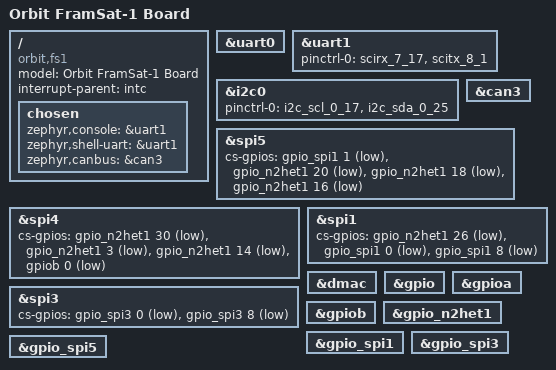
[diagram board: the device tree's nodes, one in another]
/dts-v1/;

#include <zephyr/dt-bindings/gpio/gpio.h>

#include <arm/ti/tms570ls1224.dtsi>
#include <ti/tms570/tms570ls1224-pinctrl.dtsi>

/ {
    model = "Orbit FramSat-1 Board";
    compatible = "orbit,fs1";
    interrupt-parent = <&intc>;

    chosen {
        zephyr,console = &uart1;
        zephyr,shell-uart = &uart1;
        zephyr,canbus = &can3;
    };
};

&uart0 {
    status = "okay";

};

&uart1 {
    status = "okay";
    pinctrl-0 = <&scirx_7_17 &scitx_8_1>;
    pinctrl-names = "default";
};

&i2c0 {
    pinctrl-0 = <&i2c_scl_0_17 &i2c_sda_0_25>;
    pinctrl-names = "default";
    status = "okay";
};

&can3 {
    status = "okay";
};


/* FramSat-1 SPI1 */
&spi5 {
    status = "okay";
    cs-gpios = <&gpio_spi1 1 GPIO_ACTIVE_LOW>,
               <&gpio_n2het1 20 GPIO_ACTIVE_LOW>,
               <&gpio_n2het1 18 GPIO_ACTIVE_LOW>,
               <&gpio_n2het1 16 GPIO_ACTIVE_LOW>;
};

/* FramSat-1 SPI2 */
&spi4 {
    status = "okay";
    cs-gpios = <&gpio_n2het1 30 GPIO_ACTIVE_LOW>,
               <&gpio_n2het1 3 GPIO_ACTIVE_LOW>,
               <&gpio_n2het1 14 GPIO_ACTIVE_LOW>,
               <&gpiob 0 GPIO_ACTIVE_LOW>;
};

/* FramSat-1 SPI3 */
&spi3 {
    status = "okay";
    cs-gpios = <&gpio_spi3 0 GPIO_ACTIVE_LOW>, <&gpio_spi3 8 GPIO_ACTIVE_LOW>;
};

/* FramSat-1 SPI4 */
&spi1 {
    status = "okay";
    cs-gpios = <&gpio_n2het1 26 GPIO_ACTIVE_LOW>,
               <&gpio_spi1 0 GPIO_ACTIVE_LOW>,
               <&gpio_spi1 8 GPIO_ACTIVE_LOW>;
};

&dmac {
    status = "okay";
};

&gpio {
    status = "okay";
};

&gpioa {
    status = "okay";
};

&gpiob {
    status = "okay";
};

&gpio_n2het1 {
    status = "okay";
};

&gpio_spi1 {
    status = "okay";
};

&gpio_spi3 {
    status = "okay";
};

&gpio_spi5 {
    status = "okay";
};
